# STM32U535 register map
File version: 1.7
CPU: CM33 r0p1, little endian, MPU, FPU, 4 interrupt priority bits
Registers are 32-bit, read-write, reset 0x0 unless marked. A register's access mark holds for its fields unless they carry their own. Offsets are from the block's base; [hi:lo] are bit positions; 'fields as' and 'values as' point back to an identical list.

## LPUART1 — Universal synchronous asynchronous receiver
Base 0x46002400
Same registers: SEC_LPUART1 0x56002400
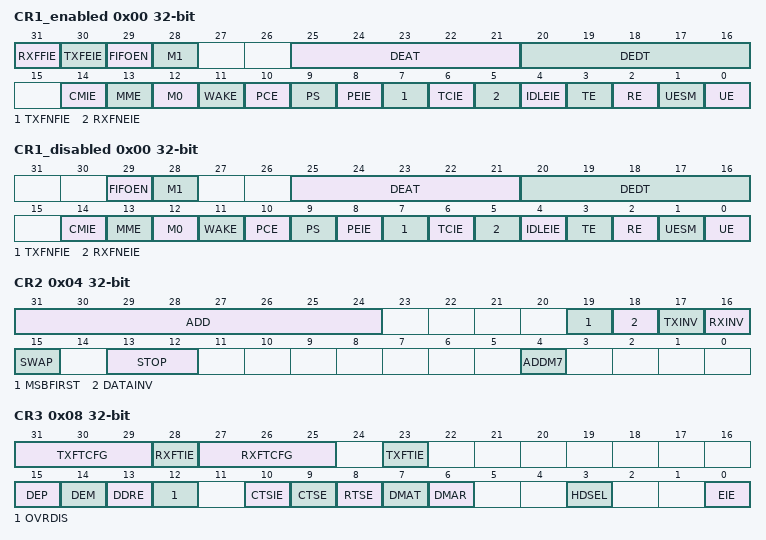
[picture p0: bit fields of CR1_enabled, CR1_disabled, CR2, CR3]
0x00 CR1_enabled — Control register 1
  [31] RXFFIE
  [30] TXFEIE
  [29] FIFOEN
  [28] M1 — Word length
  [25:21] DEAT
  [20:16] DEDT
  [14] CMIE — Character match interrupt
  [13] MME — Mute mode enable
  [12] M0 — Word length
  [11] WAKE — Receiver wakeup method
  [10] PCE — Parity control enable
  [9] PS — Parity selection
  [8] PEIE — PE interrupt enable
  [7] TXFNFIE — TXFIFO not full interrupt enable
  [6] TCIE — Transmission complete interrupt
  [5] RXFNEIE
  [4] IDLEIE — IDLE interrupt enable
  [3] TE — Transmitter enable
  [2] RE — Receiver enable
  [1] UESM — USART enable in Stop mode
  [0] UE — USART enable
0x00 CR1_disabled (alternate view of CR1_enabled) — Control register 1
  [29] FIFOEN
  [28] M1 — Word length
  [25:21] DEAT
  [20:16] DEDT
  [14] CMIE — Character match interrupt
  [13] MME — Mute mode enable
  [12] M0 — Word length
  [11] WAKE — Receiver wakeup method
  [10] PCE — Parity control enable
  [9] PS — Parity selection
  [8] PEIE — PE interrupt enable
  [7] TXFNFIE — TXFIFO not full interrupt enable
  [6] TCIE — Transmission complete interrupt
  [5] RXFNEIE
  [4] IDLEIE — IDLE interrupt enable
  [3] TE — Transmitter enable
  [2] RE — Receiver enable
  [1] UESM — USART enable in Stop mode
  [0] UE — USART enable
0x04 CR2 — Control register 2
  [31:24] ADD — Address of the LPUART node
  [19] MSBFIRST — Most significant bit first
  [18] DATAINV — Binary data inversion
  [17] TXINV — TX pin active level
  [16] RXINV — RX pin active level
  [15] SWAP — Swap TX/RX pins
  [13:12] STOP — STOP bits
  [4] ADDM7 — 7-bit Address Detection/4-bit Address
0x08 CR3 — Control register 3
  [31:29] TXFTCFG
  [28] RXFTIE
  [27:25] RXFTCFG
  [23] TXFTIE
  [15] DEP — Driver enable polarity
  [14] DEM — Driver enable mode
  [13] DDRE — DMA Disable on Reception
  [12] OVRDIS — Overrun Disable
  [10] CTSIE — CTS interrupt enable
  [9] CTSE — CTS enable
  [8] RTSE — RTS enable
  [7] DMAT — DMA enable transmitter
  [6] DMAR — DMA enable receiver
  [3] HDSEL — Half-duplex selection
  [0] EIE — Error interrupt enable
0x0C BRR — Baud rate register
  [19:0] BRR
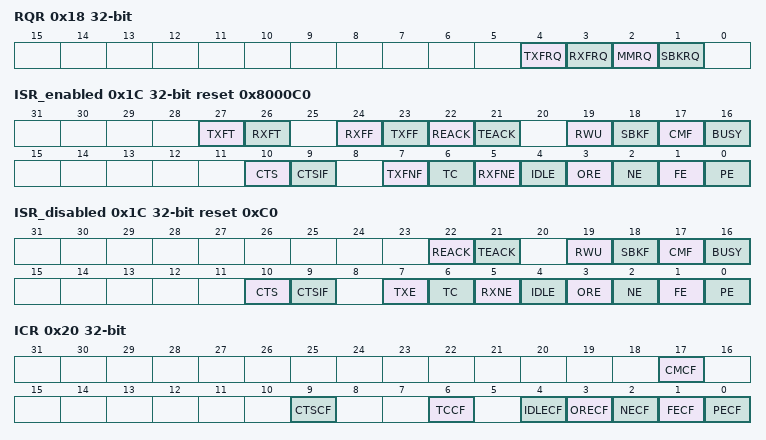
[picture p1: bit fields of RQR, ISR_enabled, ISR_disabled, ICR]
0x18 RQR wo — Request register
  [4] TXFRQ
  [3] RXFRQ — Receive data flush request
  [2] MMRQ — Mute mode request
  [1] SBKRQ — Send break request
0x1C ISR_enabled ro reset 0x8000C0 — Interrupt and status register
  [27] TXFT, [26] RXFT, [24] RXFF, [23] TXFF, [22] REACK, [21] TEACK, [19] RWU, [18] SBKF, [17] CMF, [16] BUSY, [10] CTS, [9] CTSIF, [7] TXFNF, [6] TC, [5] RXFNE, [4] IDLE, [3] ORE, [2] NE, [1] FE, [0] PE
0x1C ISR_disabled ro reset 0xC0 (alternate view of ISR_enabled) — Interrupt and status register
  [22] REACK, [21] TEACK, [19] RWU, [18] SBKF, [17] CMF, [16] BUSY, [10] CTS, [9] CTSIF, [7] TXE, [6] TC, [5] RXNE, [4] IDLE, [3] ORE, [2] NE, [1] FE, [0] PE
0x20 ICR wo — Interrupt flag clear register
  [17] CMCF — Character match clear flag
  [9] CTSCF — CTS clear flag
  [6] TCCF — Transmission complete clear
  [4] IDLECF — Idle line detected clear
  [3] ORECF — Overrun error clear flag
  [2] NECF — Noise detected clear flag
  [1] FECF — Framing error clear flag
  [0] PECF — Parity error clear flag
0x24 RDR ro — Receive data register
  [8:0] RDR — Receive data value
0x28 TDR — Transmit data register
  [8:0] TDR — Transmit data value
0x2C PRESC — prescaler register
  [3:0] PRESCALER
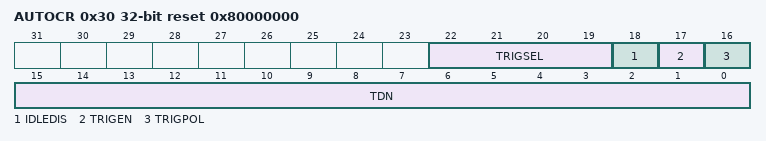
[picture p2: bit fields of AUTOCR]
0x30 AUTOCR reset 0x80000000 — Autonomous mode control register
  [22:19] TRIGSEL, [18] IDLEDIS, [17] TRIGEN, [16] TRIGPOL, [15:0] TDN

## OPAMP — Operational amplifiers
Base 0x46005000
Same registers: SEC_OPAMP 0x56005000
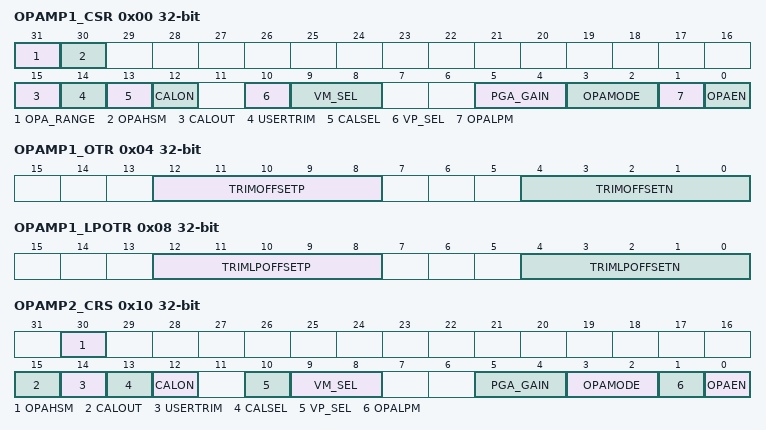
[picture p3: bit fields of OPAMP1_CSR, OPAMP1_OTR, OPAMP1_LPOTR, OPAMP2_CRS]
0x00 OPAMP1_CSR access per field — OPAMP1 control/status register
  [31] OPA_RANGE rw — OPAMP range setting
    1=OPAMP range set
  [30] OPAHSM rw — OPAMP high-speed mode
    0=normal mode (standard slew rate); 1=increased consumption to improve the slew rate
  [15] CALOUT ro — OPAMP calibration output
  [14] USERTRIM rw — factory' or user' offset trimmed values selection
    0=factory' trim code used; 1=user' trim code used
  [13] CALSEL rw — Calibration selection
    0=NMOS calibration (200 mV applied on OPAMP inputs); 1=PMOS calibration (Vless thansub>DDA less than/sub>- 200 mV applied on OPAMP inputs)
  [12] CALON rw — Calibration mode enable
    0=normal mode; 1=calibration mode (all switches opened by hardware)
  [10] VP_SEL rw — Non-inverted input selection
    0=GPIO connected to VINP; 1=DAC connected to VINP
  [9:8] VM_SEL rw — Inverting input selection
    0=GPIO connected to VINM (valid also in PGA mode for filtering); 1=dedicated low-leakage input connected to VINM (valid also in PGA mode for filtering)
  [5:4] PGA_GAIN rw — OPAMP programmable amplifier gain value
    0=internal PGA gain 2; 1=internal PGA gain 4; 2=internal PGA gain 8; 3=internal PGA gain 16
  [3:2] OPAMODE rw — OPAMP PGA mode
    2=internal PGA enabled, gain programmed in PGA_GAIN; 3=internal follower
  [1] OPALPM rw — OPAMP low-power mode
    0=normal mode; 1=low-power mode
  [0] OPAEN rw — OPAMP enable
    0=OPAMP disabled; 1=OPAMP enabled
0x04 OPAMP1_OTR (reset mask 0xFFFF0000) — OPAMP1 offset trimming register in normal mode
  [12:8] TRIMOFFSETP — Trim for PMOS differential pairs
  [4:0] TRIMOFFSETN — Trim for NMOS differential pairs
0x08 OPAMP1_LPOTR (reset mask 0xFFFF0000) — OPAMP1 offset trimming register in low-power mode
  [12:8] TRIMLPOFFSETP — Low-power mode trim for PMOS differential pairs
  [4:0] TRIMLPOFFSETN — Low-power mode trim for NMOS differential pairs
0x10 OPAMP2_CRS access per field — OPAMP2 control/status register
  [30] OPAHSM rw — OPAMP high-speed mode
    values as OPAMP1_CSR.OPAHSM
  [15] CALOUT ro — OPAMP calibration output
  [14] USERTRIM rw — factory' or user' offset trimmed values selection
    0=factory' trim code used; 1=user' trim code used
  [13] CALSEL rw — Calibration selection
    values as OPAMP1_CSR.CALSEL
  [12] CALON rw — Calibration mode enable
    values as OPAMP1_CSR.CALON
  [10] VP_SEL rw — Non inverted input selection
    0=GPIO connected to VINP; 1=DAC connected to VINP
  [9:8] VM_SEL rw — Inverting input selection
    0=GPIO connected to VINM (valid also in PGA mode for filtering); 1=dedicated low-leakage input connected to VINM (valid also
  [5:4] PGA_GAIN rw — OPAMP programmable amplifier gain value
    values as OPAMP1_CSR.PGA_GAIN
  [3:2] OPAMODE rw — OPAMP PGA mode
    values as OPAMP1_CSR.OPAMODE
  [1] OPALPM rw — OPAMP low-power mode
    0=normal mode; 1=low-power mode
  [0] OPAEN rw — OPAMP enable
    0=OPAMP disabled; 1=OPAMP enabled
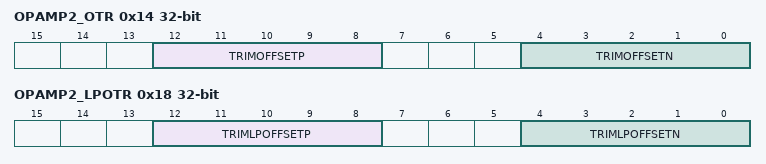
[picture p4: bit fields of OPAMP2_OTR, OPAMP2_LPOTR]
0x14 OPAMP2_OTR (reset mask 0xFFFF0000) — OPAMP2 offset trimming register in normal mode
  fields as OPAMP1_OTR
0x18 OPAMP2_LPOTR (reset mask 0xFFFF0000) — OPAMP2 offset trimming register in low-power mode
  fields as OPAMP1_LPOTR
